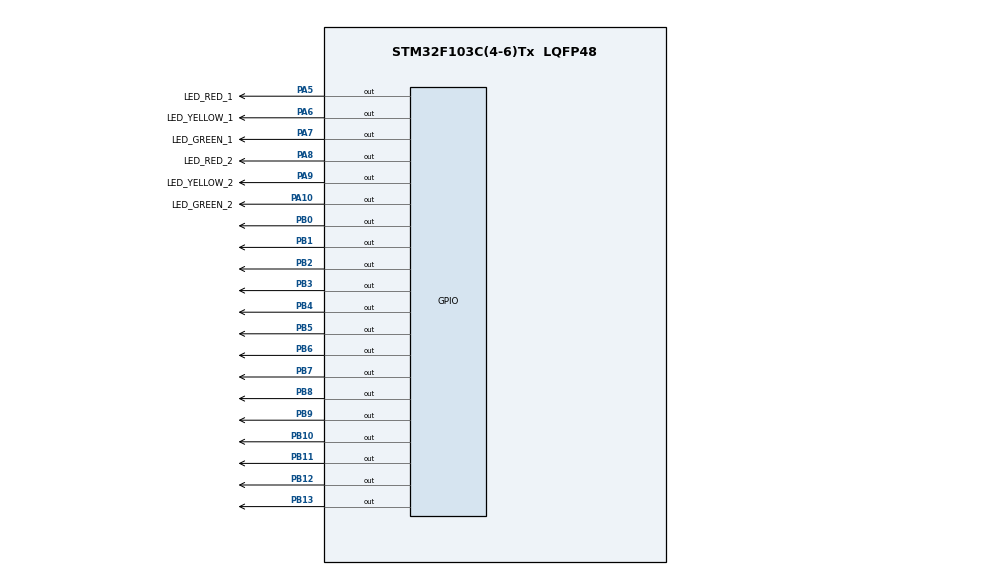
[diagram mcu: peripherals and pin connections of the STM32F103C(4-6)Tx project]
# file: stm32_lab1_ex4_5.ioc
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Mcu.Family=STM32F1
Mcu.Name=STM32F103C(4-6)Tx
Mcu.Package=LQFP48
NVIC.PriorityGroup=NVIC_PRIORITYGROUP_4
PA10.GPIO_Label=LED_GREEN_2
PA10.Signal=GPIO_Output
PA5.GPIO_Label=LED_RED_1
PA5.Signal=GPIO_Output
PA6.GPIO_Label=LED_YELLOW_1
PA6.Signal=GPIO_Output
PA7.GPIO_Label=LED_GREEN_1
PA7.Signal=GPIO_Output
PA8.GPIO_Label=LED_RED_2
PA8.Signal=GPIO_Output
PA9.GPIO_Label=LED_YELLOW_2
PA9.Signal=GPIO_Output
PB0.Signal=GPIO_Output
PB1.Signal=GPIO_Output
PB10.Signal=GPIO_Output
PB11.Signal=GPIO_Output
PB12.Signal=GPIO_Output
PB13.Signal=GPIO_Output
PB2.Signal=GPIO_Output
PB3.Signal=GPIO_Output
PB4.Signal=GPIO_Output
PB5.Signal=GPIO_Output
PB6.Signal=GPIO_Output
PB7.Signal=GPIO_Output
PB8.Signal=GPIO_Output
PB9.Signal=GPIO_Output
ProjectManager.HeapSize=0x200
ProjectManager.StackSize=0x400
ProjectManager.TargetToolchain=STM32CubeIDE
RCC.APB1Freq_Value=8000000
RCC.APB2Freq_Value=8000000
VP_SYS_VS_ND.Mode=No_Debug
board=custom

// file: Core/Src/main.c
/* USER CODE BEGIN Header */
/**
  ******************************************************************************
  * @file           : main.c
  * @brief          : Main program body
  ******************************************************************************
  * @attention
  *
  * Copyright (c) 2024 STMicroelectronics.
  * All rights reserved.
  *
  * This software is licensed under terms that can be found in the LICENSE file
  * in the root directory of this software component.
  * If no LICENSE file comes with this software, it is provided AS-IS.
  *
  ******************************************************************************
  */
/* USER CODE END Header */
#include "main.h"

/* USER CODE BEGIN PD */
#define TRAFFIC_LIGHT_DELAY 1000
/* USER CODE END PD */

void SystemClock_Config(void);
static void MX_GPIO_Init(void);

void display7SEG(int num, GPIO_TypeDef* GPIOx, uint16_t start_index){
	__IO uint16_t temp;
	switch(num){
	case 0:
		temp = 0b1000000;
		break;
	case 1:
		temp = 0b1111001;
		break;
	case 2:
		temp = 0b0100100;
		break;
	case 3:
		temp = 0b0110000;
		break;
	case 4:
		temp = 0b0011001;
		break;
	case 5:
		temp = 0b0010010;
		break;
	case 6:
		temp = 0b0000010;
		break;
	case 7:
		temp = 0b1111000;
		break;
	case 8:
		temp = 0b0;
		break;
	case 9:
		temp = 0b0010000;
		break;
	default:
		temp = !0b0;
		break;
	}
	uint16_t bitmask = 0b1111111 << start_index ;
	GPIOx->ODR = (GPIOx->ODR & ~bitmask) | (temp << start_index);
}
void toggleTrafficLight(int* state) {
    switch(*state){
    case 10:
        HAL_GPIO_TogglePin(LED_RED_1_GPIO_Port, LED_RED_1_Pin);
        HAL_GPIO_TogglePin(LED_GREEN_1_GPIO_Port, LED_GREEN_1_Pin);
        HAL_GPIO_TogglePin(LED_YELLOW_2_GPIO_Port, LED_YELLOW_2_Pin);
        HAL_GPIO_TogglePin(LED_RED_2_GPIO_Port, LED_RED_2_Pin);
        *state = 1;
        break;
    case 8:
        HAL_GPIO_TogglePin(LED_YELLOW_2_GPIO_Port, LED_YELLOW_2_Pin);
        HAL_GPIO_TogglePin(LED_GREEN_2_GPIO_Port, LED_GREEN_2_Pin);
        *state = 9;
        break;
    case 5:
        HAL_GPIO_TogglePin(LED_YELLOW_1_GPIO_Port, LED_YELLOW_1_Pin);
        HAL_GPIO_TogglePin(LED_RED_1_GPIO_Port, LED_RED_1_Pin);
        HAL_GPIO_TogglePin(LED_RED_2_GPIO_Port, LED_RED_2_Pin);
        HAL_GPIO_TogglePin(LED_GREEN_2_GPIO_Port, LED_GREEN_2_Pin);
        *state = 6;
        break;
    case 2:
        HAL_GPIO_TogglePin(LED_YELLOW_1_GPIO_Port, LED_YELLOW_1_Pin);
        HAL_GPIO_TogglePin(LED_GREEN_1_GPIO_Port, LED_GREEN_1_Pin);
        *state = 3;
        break;
    default:
        (*state)++;
        break;
    }
}
int main(void)
{

  /* MCU Configuration--------------------------------------------------------*/

  /* Reset of all peripherals, Initializes the Flash interface and the Systick. */
  HAL_Init();

  /* Configure the system clock */
  SystemClock_Config();

  /* Initialize all configured peripherals */
  MX_GPIO_Init();
  /* USER CODE BEGIN 2 */
  	  int state = 0;
      HAL_GPIO_TogglePin(LED_GREEN_1_GPIO_Port, LED_GREEN_1_Pin);
      HAL_GPIO_TogglePin(LED_RED_2_GPIO_Port, LED_RED_2_Pin);
  /* USER CODE END 2 */

  /* Infinite loop */
  /* USER CODE BEGIN WHILE */
  int counter = 0;
  while (1)
  {
	  toggleTrafficLight(&state);
      if(counter >= 10) counter = 0;
      /* This code is test
       * - the synchronization of 2 display7SEG on 1 counter
       * - the mixer 2 display7SEG on only 1 port
      */
      display7SEG(9 - counter, GPIOB, 8);
      display7SEG(counter, GPIOB, 0);
      counter++;
      HAL_Delay(TRAFFIC_LIGHT_DELAY);
  }
  /* USER CODE END 3 */
}

void SystemClock_Config(void)
{
  RCC_OscInitTypeDef RCC_OscInitStruct = {0};
  RCC_ClkInitTypeDef RCC_ClkInitStruct = {0};

  /** Initializes the RCC Oscillators according to the specified parameters
  * in the RCC_OscInitTypeDef structure.
  */
  RCC_OscInitStruct.OscillatorType = RCC_OSCILLATORTYPE_HSI;
  RCC_OscInitStruct.HSIState = RCC_HSI_ON;
  RCC_OscInitStruct.HSICalibrationValue = RCC_HSICALIBRATION_DEFAULT;
  RCC_OscInitStruct.PLL.PLLState = RCC_PLL_NONE;
  if (HAL_RCC_OscConfig(&RCC_OscInitStruct) != HAL_OK)
  {
    Error_Handler();
  }

  /** Initializes the CPU, AHB and APB buses clocks
  */
  RCC_ClkInitStruct.ClockType = RCC_CLOCKTYPE_HCLK|RCC_CLOCKTYPE_SYSCLK
                              |RCC_CLOCKTYPE_PCLK1|RCC_CLOCKTYPE_PCLK2;
  RCC_ClkInitStruct.SYSCLKSource = RCC_SYSCLKSOURCE_HSI;
  RCC_ClkInitStruct.AHBCLKDivider = RCC_SYSCLK_DIV1;
  RCC_ClkInitStruct.APB1CLKDivider = RCC_HCLK_DIV1;
  RCC_ClkInitStruct.APB2CLKDivider = RCC_HCLK_DIV1;

  if (HAL_RCC_ClockConfig(&RCC_ClkInitStruct, FLASH_LATENCY_0) != HAL_OK)
  {
    Error_Handler();
  }
}

static void MX_GPIO_Init(void)
{
  GPIO_InitTypeDef GPIO_InitStruct = {0};

  /* GPIO Ports Clock Enable */
  __HAL_RCC_GPIOA_CLK_ENABLE();
  __HAL_RCC_GPIOB_CLK_ENABLE();

  /*Configure GPIO pin Output Level */
  HAL_GPIO_WritePin(GPIOA, LED_RED_1_Pin|LED_YELLOW_1_Pin|LED_GREEN_1_Pin|LED_RED_2_Pin
                          |LED_YELLOW_2_Pin|LED_GREEN_2_Pin, GPIO_PIN_RESET);

  /*Configure GPIO pin Output Level */
  HAL_GPIO_WritePin(GPIOB, GPIO_PIN_0|GPIO_PIN_1|GPIO_PIN_2|GPIO_PIN_10
                          |GPIO_PIN_11|GPIO_PIN_12|GPIO_PIN_13|GPIO_PIN_3
                          |GPIO_PIN_4|GPIO_PIN_5|GPIO_PIN_6|GPIO_PIN_7
                          |GPIO_PIN_8|GPIO_PIN_9, GPIO_PIN_RESET);

  /*Configure GPIO pins : LED_RED_1_Pin LED_YELLOW_1_Pin LED_GREEN_1_Pin LED_RED_2_Pin
                           LED_YELLOW_2_Pin LED_GREEN_2_Pin */
  GPIO_InitStruct.Pin = LED_RED_1_Pin|LED_YELLOW_1_Pin|LED_GREEN_1_Pin|LED_RED_2_Pin
                          |LED_YELLOW_2_Pin|LED_GREEN_2_Pin;
  GPIO_InitStruct.Mode = GPIO_MODE_OUTPUT_PP;
  GPIO_InitStruct.Pull = GPIO_NOPULL;
  GPIO_InitStruct.Speed = GPIO_SPEED_FREQ_LOW;
  HAL_GPIO_Init(GPIOA, &GPIO_InitStruct);

  /*Configure GPIO pins : PB0 PB1 PB2 PB10
                           PB11 PB12 PB13 PB3
                           PB4 PB5 PB6 PB7
                           PB8 PB9 */
  GPIO_InitStruct.Pin = GPIO_PIN_0|GPIO_PIN_1|GPIO_PIN_2|GPIO_PIN_10
                          |GPIO_PIN_11|GPIO_PIN_12|GPIO_PIN_13|GPIO_PIN_3
                          |GPIO_PIN_4|GPIO_PIN_5|GPIO_PIN_6|GPIO_PIN_7
                          |GPIO_PIN_8|GPIO_PIN_9;
  GPIO_InitStruct.Mode = GPIO_MODE_OUTPUT_PP;
  GPIO_InitStruct.Pull = GPIO_NOPULL;
  GPIO_InitStruct.Speed = GPIO_SPEED_FREQ_LOW;
  HAL_GPIO_Init(GPIOB, &GPIO_InitStruct);

}

void Error_Handler(void)
{
  __disable_irq();
  while (1)
  {
  }
}
